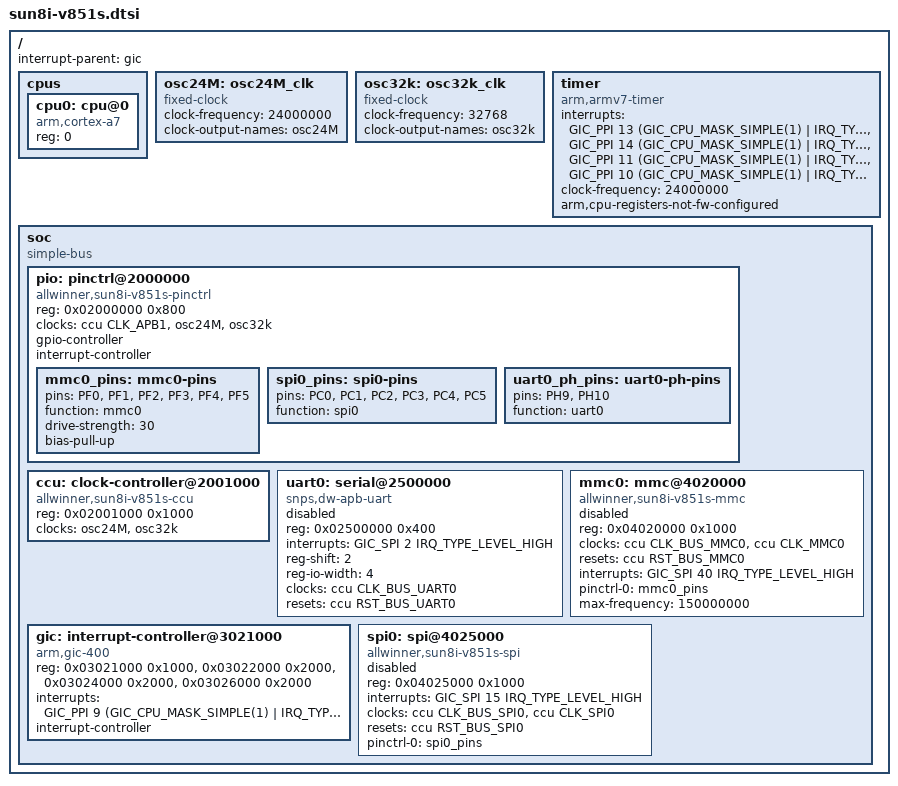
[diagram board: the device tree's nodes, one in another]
// SPDX-License-Identifier: (GPL-2.0+ OR MIT)
/*
 * Allwinner V851s (sun8iw21p1): one Cortex-A7 with the D1/T113's
 * peripherals, clocks and memory map. Only what U-Boot uses: the D1's
 * CCU has the H6's bus gates and module clocks at the H6's offsets, so
 * the clock and reset indices are the H6's, as on the V831.
 */

#include <dt-bindings/interrupt-controller/arm-gic.h>
#include <dt-bindings/clock/sun50i-h6-ccu.h>
#include <dt-bindings/reset/sun50i-h6-ccu.h>

/ {
	interrupt-parent = <&gic>;
	#address-cells = <1>;
	#size-cells = <1>;

	cpus {
		#address-cells = <1>;
		#size-cells = <0>;

		cpu0: cpu@0 {
			compatible = "arm,cortex-a7";
			device_type = "cpu";
			reg = <0>;
		};
	};

	osc24M: osc24M_clk {
		#clock-cells = <0>;
		compatible = "fixed-clock";
		clock-frequency = <24000000>;
		clock-output-names = "osc24M";
	};

	osc32k: osc32k_clk {
		#clock-cells = <0>;
		compatible = "fixed-clock";
		clock-frequency = <32768>;
		clock-output-names = "osc32k";
	};

	timer {
		compatible = "arm,armv7-timer";
		interrupts = <GIC_PPI 13 (GIC_CPU_MASK_SIMPLE(1) | IRQ_TYPE_LEVEL_LOW)>,
			     <GIC_PPI 14 (GIC_CPU_MASK_SIMPLE(1) | IRQ_TYPE_LEVEL_LOW)>,
			     <GIC_PPI 11 (GIC_CPU_MASK_SIMPLE(1) | IRQ_TYPE_LEVEL_LOW)>,
			     <GIC_PPI 10 (GIC_CPU_MASK_SIMPLE(1) | IRQ_TYPE_LEVEL_LOW)>;
		clock-frequency = <24000000>;
		arm,cpu-registers-not-fw-configured;
	};

	soc {
		compatible = "simple-bus";
		#address-cells = <1>;
		#size-cells = <1>;
		ranges;

		pio: pinctrl@2000000 {
			compatible = "allwinner,sun8i-v851s-pinctrl";
			reg = <0x02000000 0x800>;
			clocks = <&ccu CLK_APB1>, <&osc24M>, <&osc32k>;
			clock-names = "apb", "hosc", "losc";
			gpio-controller;
			#gpio-cells = <3>;
			interrupt-controller;
			#interrupt-cells = <3>;

			mmc0_pins: mmc0-pins {
				pins = "PF0", "PF1", "PF2", "PF3", "PF4", "PF5";
				function = "mmc0";
				drive-strength = <30>;
				bias-pull-up;
			};

			spi0_pins: spi0-pins {
				pins = "PC0", "PC1", "PC2", "PC3", "PC4", "PC5";
				function = "spi0";
			};

			uart0_ph_pins: uart0-ph-pins {
				pins = "PH9", "PH10";
				function = "uart0";
			};
		};

		ccu: clock-controller@2001000 {
			compatible = "allwinner,sun8i-v851s-ccu";
			reg = <0x02001000 0x1000>;
			clocks = <&osc24M>, <&osc32k>;
			clock-names = "hosc", "losc";
			#clock-cells = <1>;
			#reset-cells = <1>;
		};

		uart0: serial@2500000 {
			compatible = "snps,dw-apb-uart";
			reg = <0x02500000 0x400>;
			interrupts = <GIC_SPI 2 IRQ_TYPE_LEVEL_HIGH>;
			reg-shift = <2>;
			reg-io-width = <4>;
			clocks = <&ccu CLK_BUS_UART0>;
			resets = <&ccu RST_BUS_UART0>;
			status = "disabled";
		};

		gic: interrupt-controller@3021000 {
			compatible = "arm,gic-400";
			reg = <0x03021000 0x1000>,
			      <0x03022000 0x2000>,
			      <0x03024000 0x2000>,
			      <0x03026000 0x2000>;
			interrupts = <GIC_PPI 9 (GIC_CPU_MASK_SIMPLE(1) | IRQ_TYPE_LEVEL_HIGH)>;
			interrupt-controller;
			#interrupt-cells = <3>;
		};

		mmc0: mmc@4020000 {
			compatible = "allwinner,sun8i-v851s-mmc",
				     "allwinner,sun50i-a100-mmc";
			reg = <0x04020000 0x1000>;
			clocks = <&ccu CLK_BUS_MMC0>, <&ccu CLK_MMC0>;
			clock-names = "ahb", "mmc";
			resets = <&ccu RST_BUS_MMC0>;
			reset-names = "ahb";
			interrupts = <GIC_SPI 40 IRQ_TYPE_LEVEL_HIGH>;
			pinctrl-names = "default";
			pinctrl-0 = <&mmc0_pins>;
			max-frequency = <150000000>;
			status = "disabled";
			#address-cells = <1>;
			#size-cells = <0>;
		};

		spi0: spi@4025000 {
			compatible = "allwinner,sun8i-v851s-spi",
				     "allwinner,sun50i-r329-spi";
			reg = <0x04025000 0x1000>;
			interrupts = <GIC_SPI 15 IRQ_TYPE_LEVEL_HIGH>;
			clocks = <&ccu CLK_BUS_SPI0>, <&ccu CLK_SPI0>;
			clock-names = "ahb", "mod";
			resets = <&ccu RST_BUS_SPI0>;
			pinctrl-names = "default";
			pinctrl-0 = <&spi0_pins>;
			status = "disabled";
			#address-cells = <1>;
			#size-cells = <0>;
		};
	};
};
